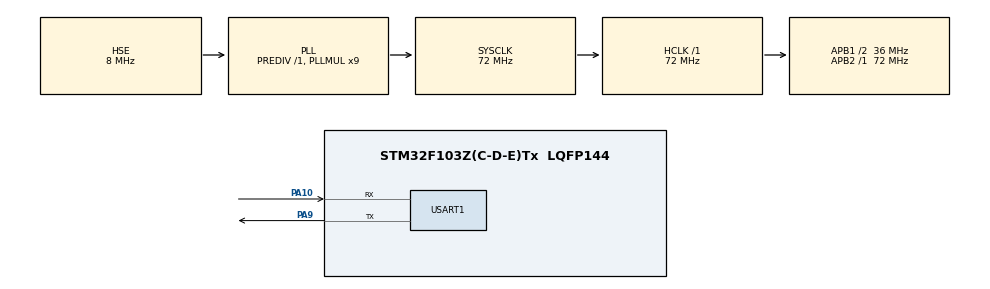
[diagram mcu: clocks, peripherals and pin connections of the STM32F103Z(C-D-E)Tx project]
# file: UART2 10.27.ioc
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Mcu.Family=STM32F1
Mcu.Name=STM32F103Z(C-D-E)Tx
Mcu.Package=LQFP144
NVIC.PriorityGroup=NVIC_PRIORITYGROUP_4
NVIC.USART1_IRQn=true\:0\:0\:false\:false\:true\:true\:true\:true
OSC_IN.Mode=HSE-External-Oscillator
OSC_IN.Signal=RCC_OSC_IN
OSC_OUT.Mode=HSE-External-Oscillator
OSC_OUT.Signal=RCC_OSC_OUT
PA10.Mode=Asynchronous
PA10.Signal=USART1_RX
PA13.Mode=Serial_Wire
PA13.Signal=SYS_JTMS-SWDIO
PA14.Mode=Serial_Wire
PA14.Signal=SYS_JTCK-SWCLK
PA9.Mode=Asynchronous
PA9.Signal=USART1_TX
ProjectManager.HeapSize=0x200
ProjectManager.StackSize=0x400
ProjectManager.TargetToolchain=MDK-ARM V5.32
RCC.AHBFreq_Value=72000000
RCC.APB1CLKDivider=RCC_HCLK_DIV2
RCC.APB1Freq_Value=36000000
RCC.APB1TimFreq_Value=72000000
RCC.APB2Freq_Value=72000000
RCC.APB2TimFreq_Value=72000000
RCC.HCLKFreq_Value=72000000
RCC.PLLMUL=RCC_PLL_MUL9
RCC.PLLSourceVirtual=RCC_PLLSOURCE_HSE
RCC.SYSCLKFreq_VALUE=72000000
RCC.SYSCLKSource=RCC_SYSCLKSOURCE_PLLCLK
RCC.USBFreq_Value=72000000
USART1.VirtualMode=VM_ASYNC
board=custom

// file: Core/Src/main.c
/* USER CODE BEGIN Header */
/**
  ******************************************************************************
  * @file           : main.c
  * @brief          : Main program body
  ******************************************************************************
  * @attention
  *
  * Copyright (c) 2025 STMicroelectronics.
  * All rights reserved.
  *
  * This software is licensed under terms that can be found in the LICENSE file
  * in the root directory of this software component.
  * If no LICENSE file comes with this software, it is provided AS-IS.
  *
  ******************************************************************************
  */
/* USER CODE END Header */
#include "main.h"

/* USER CODE BEGIN Includes */
#include <string.h>
#include <stdio.h>
/* USER CODE END Includes */

UART_HandleTypeDef huart1;

/* USER CODE BEGIN PV */
// Receive state enum
typedef enum {
    WAIT_HEAD1,
    WAIT_HEAD2,
    RECEIVE_DATA
} RxState;

// Data packet structure
typedef struct {
    uint8_t header1;
    uint8_t header2;
    uint8_t id;
    uint8_t count;
    uint8_t distances[4];
} DataPacket;

// Global variables
RxState rx_state = WAIT_HEAD1;
uint8_t rx_data;
uint8_t data_index = 0;
DataPacket packet;
uint8_t packet_ready = 0;
/* USER CODE END PV */

void SystemClock_Config(void);
static void MX_GPIO_Init(void);
static void MX_USART1_UART_Init(void);
/* USER CODE BEGIN PFP */
void ProcessPacket(void);
/* USER CODE END PFP */

int main(void)
{

  /* MCU Configuration--------------------------------------------------------*/

  /* Reset of all peripherals, Initializes the Flash interface and the Systick. */
  HAL_Init();

  /* Configure the system clock */
  SystemClock_Config();

  /* Initialize all configured peripherals */
  MX_GPIO_Init();
  MX_USART1_UART_Init();
  /* USER CODE BEGIN 2 */
  // Enable USART1 interrupt
  HAL_NVIC_SetPriority(USART1_IRQn, 0, 0);
  HAL_NVIC_EnableIRQ(USART1_IRQn);

  // Start UART receive interrupt
  HAL_UART_Receive_IT(&huart1, &rx_data, 1);

  // Send startup message
  char welcome[] = "System Ready\r\n";
  HAL_UART_Transmit(&huart1, (uint8_t*)welcome, strlen(welcome), 1000);
  /* USER CODE END 2 */

  /* Infinite loop */
  while (1)
  {

    /* USER CODE BEGIN 3 */
    ProcessPacket();
    HAL_Delay(10);
  }
  /* USER CODE END 3 */
}

void SystemClock_Config(void)
{
  RCC_OscInitTypeDef RCC_OscInitStruct = {0};
  RCC_ClkInitTypeDef RCC_ClkInitStruct = {0};

  /** Initializes the RCC Oscillators according to the specified parameters
  * in the RCC_OscInitTypeDef structure.
  */
  RCC_OscInitStruct.OscillatorType = RCC_OSCILLATORTYPE_HSE;
  RCC_OscInitStruct.HSEState = RCC_HSE_ON;
  RCC_OscInitStruct.HSEPredivValue = RCC_HSE_PREDIV_DIV1;
  RCC_OscInitStruct.HSIState = RCC_HSI_ON;
  RCC_OscInitStruct.PLL.PLLState = RCC_PLL_ON;
  RCC_OscInitStruct.PLL.PLLSource = RCC_PLLSOURCE_HSE;
  RCC_OscInitStruct.PLL.PLLMUL = RCC_PLL_MUL9;
  if (HAL_RCC_OscConfig(&RCC_OscInitStruct) != HAL_OK)
  {
    Error_Handler();
  }

  /** Initializes the CPU, AHB and APB buses clocks
  */
  RCC_ClkInitStruct.ClockType = RCC_CLOCKTYPE_HCLK|RCC_CLOCKTYPE_SYSCLK
                              |RCC_CLOCKTYPE_PCLK1|RCC_CLOCKTYPE_PCLK2;
  RCC_ClkInitStruct.SYSCLKSource = RCC_SYSCLKSOURCE_PLLCLK;
  RCC_ClkInitStruct.AHBCLKDivider = RCC_SYSCLK_DIV1;
  RCC_ClkInitStruct.APB1CLKDivider = RCC_HCLK_DIV2;
  RCC_ClkInitStruct.APB2CLKDivider = RCC_HCLK_DIV1;

  if (HAL_RCC_ClockConfig(&RCC_ClkInitStruct, FLASH_LATENCY_2) != HAL_OK)
  {
    Error_Handler();
  }
}

static void MX_USART1_UART_Init(void)
{

  huart1.Instance = USART1;
  huart1.Init.BaudRate = 115200;
  huart1.Init.WordLength = UART_WORDLENGTH_8B;
  huart1.Init.StopBits = UART_STOPBITS_1;
  huart1.Init.Parity = UART_PARITY_NONE;
  huart1.Init.Mode = UART_MODE_TX_RX;
  huart1.Init.HwFlowCtl = UART_HWCONTROL_NONE;
  huart1.Init.OverSampling = UART_OVERSAMPLING_16;
  if (HAL_UART_Init(&huart1) != HAL_OK)
  {
    Error_Handler();
  }

}

static void MX_GPIO_Init(void)
{

  /* GPIO Ports Clock Enable */
  __HAL_RCC_GPIOA_CLK_ENABLE();

}

/* USER CODE BEGIN 4 */
// UART receive interrupt callback function
void HAL_UART_RxCpltCallback(UART_HandleTypeDef *huart)
{
    if (huart->Instance == USART1) {
        if (rx_state == WAIT_HEAD1) {
            if (rx_data == 0xCC) {
                packet.header1 = rx_data;
                rx_state = WAIT_HEAD2;
            }
        }
        else if (rx_state == WAIT_HEAD2) {
            if (rx_data == 0xDD) {
                packet.header2 = rx_data;
                rx_state = RECEIVE_DATA;
                data_index = 0;
            } else {
                rx_state = WAIT_HEAD1;
            }
        }
        else if (rx_state == RECEIVE_DATA) {
            if (data_index == 0) {
                packet.id = rx_data;
            }
            else if (data_index == 1) {
                packet.count = rx_data;
                if (packet.count > 4) packet.count = 4;
            }
            else if (data_index >= 2 && data_index <= 5) {
                packet.distances[data_index - 2] = rx_data;
            }

            data_index++;

            if (data_index >= 6) {
                packet_ready = 1;
                rx_state = WAIT_HEAD1;
            }
        }

        // Restart receive interrupt
        HAL_UART_Receive_IT(&huart1, &rx_data, 1);
    }
}

// Process packet function
void ProcessPacket(void)
{
    if (packet_ready) {
        packet_ready = 0;

        char tx_buffer[64];

        // Use sprintf to format output string
        sprintf(tx_buffer, "ID:%02X Count:%d Distance:%d %d %d %d\r\n",
                packet.id,
                packet.count,
                packet.distances[0],
                packet.distances[1],
                packet.distances[2],
                packet.distances[3]);

        // Send response via UART
        HAL_UART_Transmit(&huart1, (uint8_t*)tx_buffer, strlen(tx_buffer), 1000);

        // 1 second delay (as required)
        HAL_Delay(1000);
    }
}
/* USER CODE END 4 */

void Error_Handler(void)
{
  __disable_irq();
  while (1)
  {
  }
}
